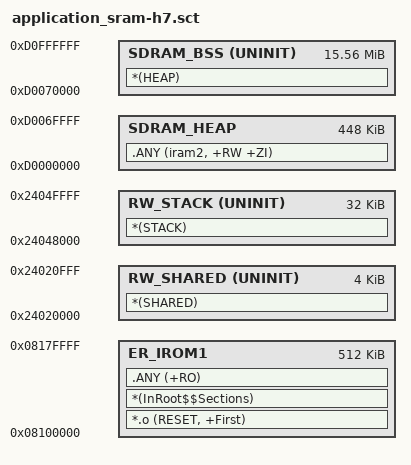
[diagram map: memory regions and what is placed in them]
LR_IROM1 0x08100000 0x00080000 {    ; load region size_region
  ER_IROM1 0x08100000 0x00080000 {  ; load address = execution address
   *.o (RESET, +First)
   *(InRoot$$Sections)
   .ANY (+RO)
  }
  RW_SHARED 0x24020000 UNINIT 0x00001000  { ;SRAM1
   *(SHARED)
  }
  RW_STACK 0x24048000 UNINIT 0x00008000  { ;SRAM2
   *(STACK)
  }
  SDRAM_HEAP 0xD0000000 0x00070000 {  ; SDRAM
    .ANY (iram2, +RW +ZI)
  }
  SDRAM_BSS 0xD0070000 UNINIT 0x00f90000  {  ; SDRAM
    *(HEAP)
  }
}

;STM32F769 MEMORY MAP:
;
;SRAM2  (16 KB)     0x2007 C000 - 0x2007 FFFF
;SRAM1  (368 KB)    0x2002 0000 - 0x2007 BFFF
;DTCM   (128 KB)    0x2000 0000 - 0x2001 FFFF
;ITCM RAM (16kb)    0x0000 0000 - 0x0000 3FFF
